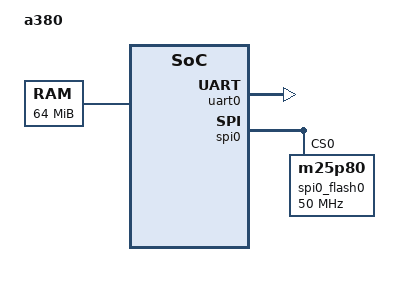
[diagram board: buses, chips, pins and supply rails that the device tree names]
/*
 * Copyright (C) 2014 Faraday, Inc. (www.faraday-tech.com)
 *
 * This program is free software; you can redistribute it and/or modify
 * it under the terms of the GNU General Public License version 2 as
 * published by the Free Software Foundation.
 */
 /dts-v1/;
/  {
	model = "a380";
	compatible = "arm,faraday-soc";
    u-boot,dm-pre-reloc;
	#address-cells = <1>;
	#size-cells = <1>;
	
	aliases {
		serial0 = &uart0;
		spi0 = &spi0;
	};
	
	cpus {
		#address-cells = <1>;
		#size-cells = <0>;

		cpu@0 {
			device_type = "cpu";
			compatible = "arm,arm926ej-s";
			reg = <0>;
			clock-names = "cpu";
		};
	};

	memory@40000000 {
		device_type = "memory";
		reg = <0x40000000 0x04000000>;
	};
		
	chosen {
		bootargs = "mem=512M console=ttyS0,38400";
        stdout-path = "serial0:38400n8";
	};
		
	uart0: uart@90400000 {
		compatible = "of_serial,ns16550_serial", "ns16550";
		#clock-frequency = <18432000>;
		reg = <0x90400000 0x1000>;		
		reg-offset = <0>;
		reg-shift = <2>;
		reg-io-width = <4>;
		no-loopback-test;
	};

    spi0: spi@0xC0A00000 {
		compatible = "faraday,ftspi020_spi";
		reg = <0xC0A00000 0x200>;
		num-cs = <4>;
		cs = <0>;
		max_hz = <25000000>;
		interrupts = <54>;
		#address-cells = <1>;
		#size-cells = <0>;
		spi0_flash0: spi0_flash0@0 {
			compatible = "m25p80";
			#address-cells = <1>;
			#size-cells = <1>;
			spi-max-frequency = <50000000>;
			reg = <0>;

			spi0_flash0@00000000 {
			label = "spi0_flash0";
            reg = <0x0 0x100000>;
            };
	    };
     };
 };
